# STM32WB55x register map
File version: 1.0
CPU: CM4 r0p1, little endian, 4 interrupt priority bits
Registers are 32-bit, read-write, reset 0x0 unless marked. A register's access mark holds for its fields unless they carry their own. Offsets are from the block's base; [hi:lo] are bit positions; {n}, {i} and the like mark numbered series; 'fields as' and 'values as' point back to an identical list.

## RTC
Base 0x40002800
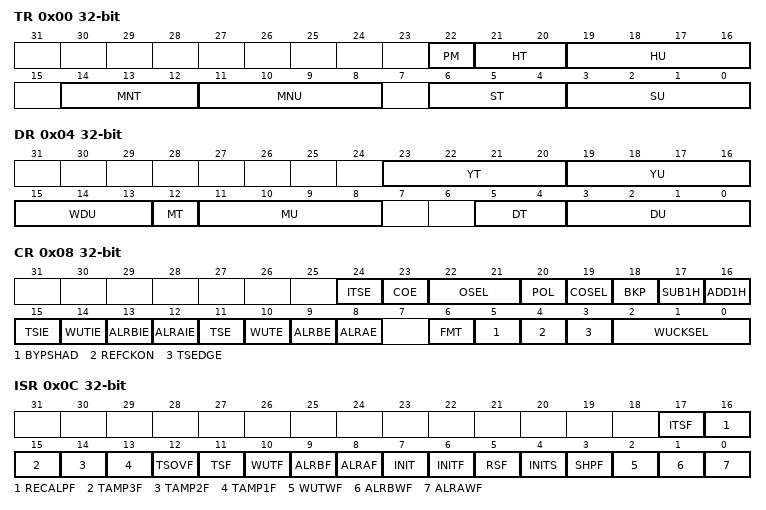
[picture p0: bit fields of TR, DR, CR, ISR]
0x00 TR
  [22] PM, [21:20] HT, [19:16] HU, [14:12] MNT, [11:8] MNU, [6:4] ST, [3:0] SU
0x04 DR
  [23:20] YT, [19:16] YU, [15:13] WDU, [12] MT, [11:8] MU, [5:4] DT, [3:0] DU
0x08 CR
  [24] ITSE, [23] COE, [22:21] OSEL, [20] POL, [19] COSEL, [18] BKP, [17] SUB1H, [16] ADD1H, [15] TSIE, [14] WUTIE, [13] ALRBIE, [12] ALRAIE, [11] TSE, [10] WUTE, [9] ALRBE, [8] ALRAE, [6] FMT, [5] BYPSHAD, [4] REFCKON, [3] TSEDGE, [2:0] WUCKSEL
0x0C ISR
  [17] ITSF, [16] RECALPF, [15] TAMP3F, [14] TAMP2F, [13] TAMP1F, [12] TSOVF, [11] TSF, [10] WUTF, [9] ALRBF, [8] ALRAF, [7] INIT, [6] INITF, [5] RSF, [4] INITS, [3] SHPF, [2] WUTWF, [1] ALRBWF, [0] ALRAWF
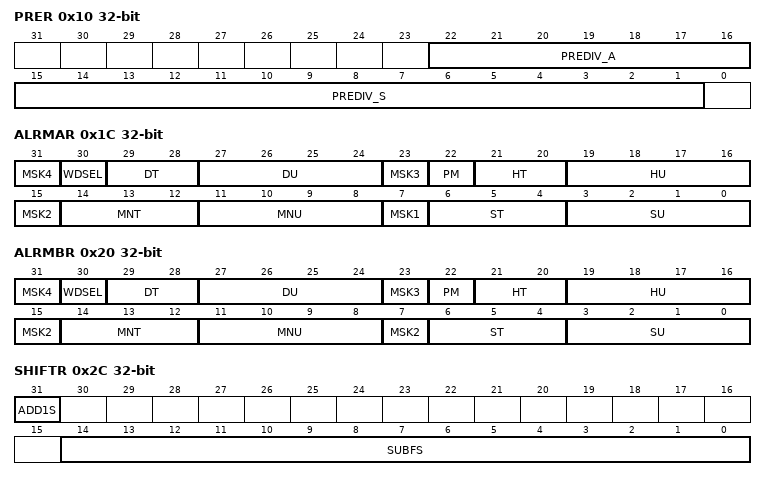
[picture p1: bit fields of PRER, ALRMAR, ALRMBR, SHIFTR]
0x10 PRER
  [22:16] PREDIV_A, [15:1] PREDIV_S
0x14 WUTR
  [15:0] WUT
0x1C ALRMAR
  [8n-1] MSK{n} (n=1..4), [30] WDSEL, [29:28] DT, [27:24] DU, [22] PM, [21:20] HT, [19:16] HU, [14:12] MNT, [11:8] MNU, [6:4] ST, [3:0] SU
0x20 ALRMBR
  [31] MSK4, [30] WDSEL, [29:28] DT, [27:24] DU, [23] MSK3, [22] PM, [21:20] HT, [19:16] HU, [15] MSK2, [14:12] MNT, [11:8] MNU, [7] MSK2, [6:4] ST, [3:0] SU
0x24 WPR
  [7:0] KEY
0x28 SSR
  [15:0] SS
0x2C SHIFTR
  [31] ADD1S, [14:0] SUBFS
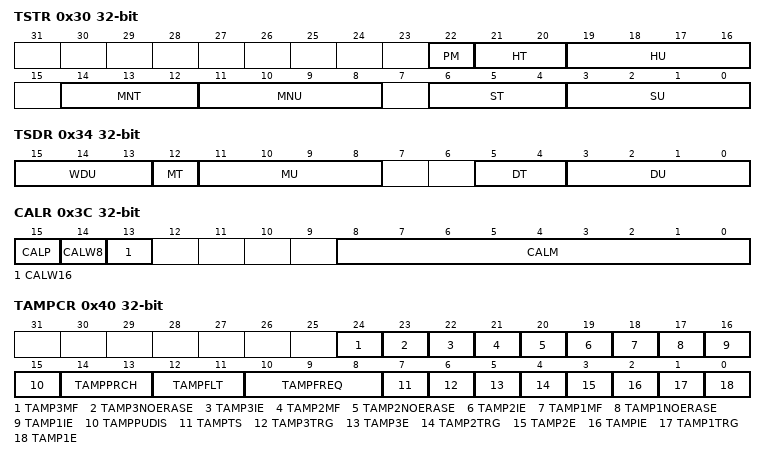
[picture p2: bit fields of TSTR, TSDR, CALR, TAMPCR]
0x30 TSTR
  fields as TR
0x34 TSDR
  [15:13] WDU, [12] MT, [11:8] MU, [5:4] DT, [3:0] DU
0x38 TSSSR
  [15:0] SS
0x3C CALR
  [15] CALP, [14] CALW8, [13] CALW16, [8:0] CALM
0x40 TAMPCR
  [24] TAMP3MF, [23] TAMP3NOERASE, [22] TAMP3IE, [21] TAMP2MF, [20] TAMP2NOERASE, [19] TAMP2IE, [18] TAMP1MF, [17] TAMP1NOERASE, [16] TAMP1IE, [15] TAMPPUDIS, [14:13] TAMPPRCH, [12:11] TAMPFLT, [10:8] TAMPFREQ, [7] TAMPTS, [6] TAMP3TRG, [5] TAMP3E, [4] TAMP2TRG, [3] TAMP2E, [2] TAMPIE, [1] TAMP1TRG, [0] TAMP1E
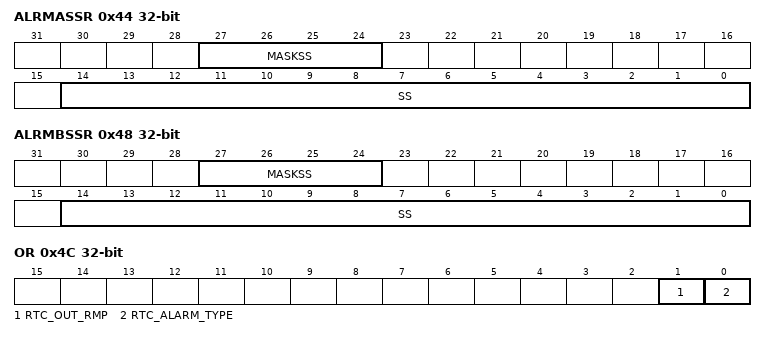
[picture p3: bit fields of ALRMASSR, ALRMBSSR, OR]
0x44 ALRMASSR
  [27:24] MASKSS, [14:0] SS
0x48 ALRMBSSR
  [27:24] MASKSS, [14:0] SS
0x4C OR
  [1] RTC_OUT_RMP, [0] RTC_ALARM_TYPE
0x50 BKP0R
  [31:0] BKP
{0x50+4i} RKP{i}R (i=1..18)
  [31:0] BKP
0x9C BKP19R
  [31:0] BKP

## GPIOA
Base 0x48000000
Same registers: GPIOB 0x48000400, GPIOC 0x48000800, GPIOD 0x48000C00, GPIOE 0x48001000, GPIOH 0x48001C00
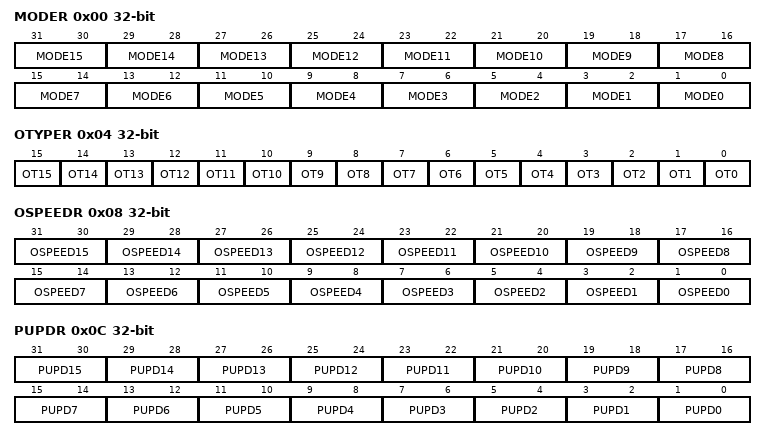
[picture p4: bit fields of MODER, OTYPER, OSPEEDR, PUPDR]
0x00 MODER
  [2n+1:2n] MODE{n} (n=0..15)
0x04 OTYPER
  [n] OT{n} (n=0..15)
0x08 OSPEEDR
  [2n+1:2n] OSPEED{n} (n=0..15)
0x0C PUPDR
  [2n+1:2n] PUPD{n} (n=0..15)
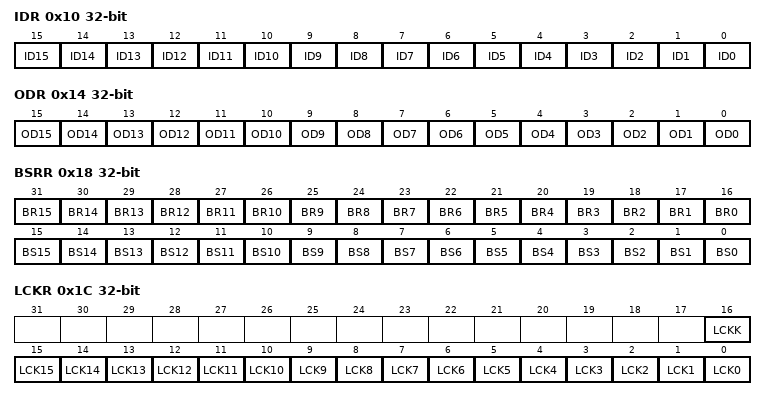
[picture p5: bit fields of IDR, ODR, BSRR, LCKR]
0x10 IDR
  [n] ID{n} (n=0..15)
0x14 ODR
  [n] OD{n} (n=0..15)
0x18 BSRR
  [n+16] BR{n} (n=0..15), [n] BS{n} (n=0..15)
0x1C LCKR
  [16] LCKK, [n] LCK{n} (n=0..15)
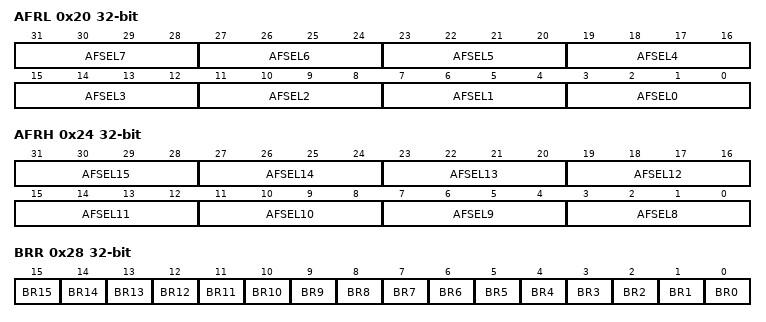
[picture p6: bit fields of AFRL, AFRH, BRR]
0x20 AFRL
  [4n+3:4n] AFSEL{n} (n=0..7)
0x24 AFRH
  [4n-29:4n-32] AFSEL{n} (n=8..15)
0x28 BRR
  [n] BR{n} (n=0..15)

## TIM1
Base 0x40012C00
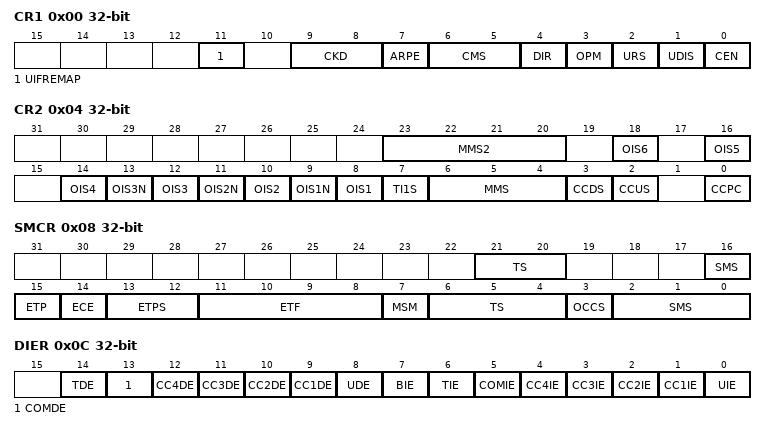
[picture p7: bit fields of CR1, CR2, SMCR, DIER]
0x00 CR1
  [11] UIFREMAP, [9:8] CKD, [7] ARPE, [6:5] CMS, [4] DIR, [3] OPM, [2] URS, [1] UDIS, [0] CEN
0x04 CR2
  [23:20] MMS2, [2n+6] OIS{n} (n=1..6), [13] OIS3N, [11] OIS2N, [9] OIS1N, [7] TI1S, [6:4] MMS, [3] CCDS, [2] CCUS, [0] CCPC
0x08 SMCR
  [21:20] TS, [16] SMS, [15] ETP, [14] ECE, [13:12] ETPS, [11:8] ETF, [7] MSM, [6:4] TS, [3] OCCS, [2:0] SMS
0x0C DIER
  [14] TDE, [13] COMDE, [n+8] CC{n}DE (n=1..4), [8] UDE, [7] BIE, [6] TIE, [5] COMIE, [n] CC{n}IE (n=1..4), [0] UIE
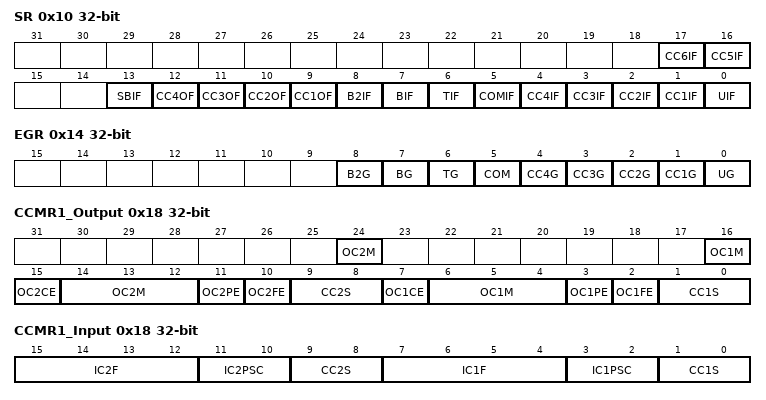
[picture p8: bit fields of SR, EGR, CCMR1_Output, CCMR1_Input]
0x10 SR
  [17] CC6IF, [16] CC5IF, [13] SBIF, [n+8] CC{n}OF (n=1..4), [8] B2IF, [7] BIF, [6] TIF, [5] COMIF, [n] CC{n}IF (n=1..4), [0] UIF
0x14 EGR
  [8] B2G, [7] BG, [6] TG, [5] COM, [n] CC{n}G (n=1..4), [0] UG
0x18 CCMR1_Output
  [24] OC2M, [16] OC1M, [15] OC2CE, [14:12] OC2M, [11] OC2PE, [10] OC2FE, [9:8] CC2S, [7] OC1CE, [6:4] OC1M, [3] OC1PE, [2] OC1FE, [1:0] CC1S
0x18 CCMR1_Input
  [15:12] IC2F, [11:10] IC2PSC, [9:8] CC2S, [7:4] IC1F, [3:2] IC1PSC, [1:0] CC1S
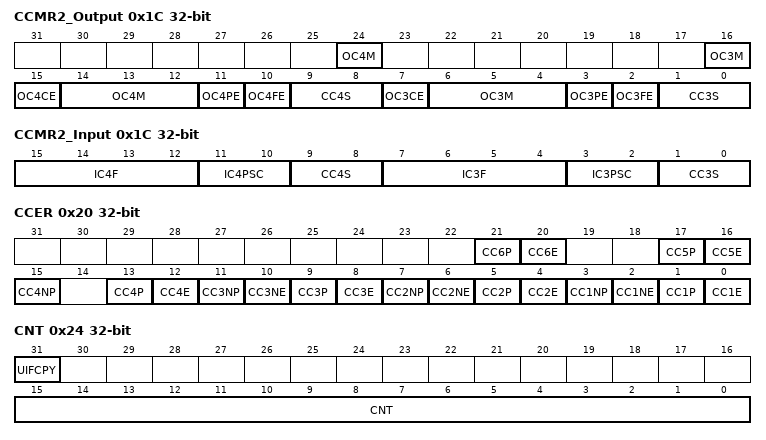
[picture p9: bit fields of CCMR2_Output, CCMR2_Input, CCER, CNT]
0x1C CCMR2_Output
  [24] OC4M, [16] OC3M, [15] OC4CE, [14:12] OC4M, [11] OC4PE, [10] OC4FE, [9:8] CC4S, [7] OC3CE, [6:4] OC3M, [3] OC3PE, [2] OC3FE, [1:0] CC3S
0x1C CCMR2_Input
  [15:12] IC4F, [11:10] IC4PSC, [9:8] CC4S, [7:4] IC3F, [3:2] IC3PSC, [1:0] CC3S
0x20 CCER
  [4n-3] CC{n}P (n=1..6), [4n-4] CC{n}E (n=1..6), [4n-1] CC{n}NP (n=1..4), [10] CC3NE, [6] CC2NE, [2] CC1NE
0x24 CNT
  [31] UIFCPY, [15:0] CNT
0x28 PSC
  [15:0] PSC
0x2C ARR
  [15:0] ARR
0x30 RCR
  [15:0] REP
{0x30+4i} CCR{i} (i=1..4)
  [15:0] CCR{i}
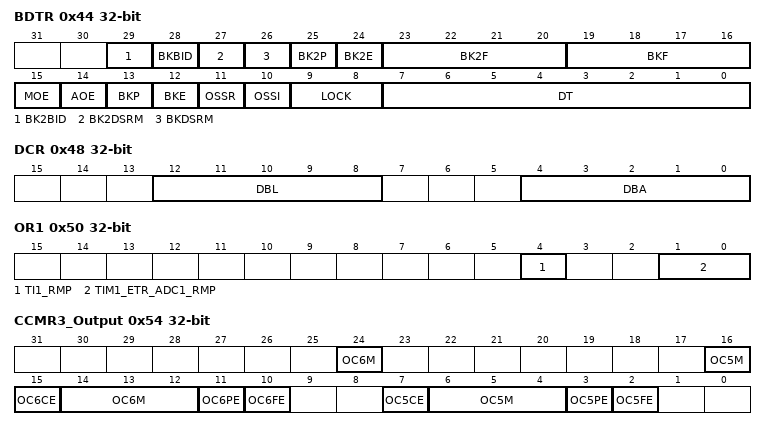
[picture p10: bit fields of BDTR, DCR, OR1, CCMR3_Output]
0x44 BDTR
  [29] BK2BID, [28] BKBID, [27] BK2DSRM, [26] BKDSRM, [25] BK2P, [24] BK2E, [23:20] BK2F, [19:16] BKF, [15] MOE, [14] AOE, [13] BKP, [12] BKE, [11] OSSR, [10] OSSI, [9:8] LOCK, [7:0] DT
0x48 DCR
  [12:8] DBL, [4:0] DBA
0x4C DMAR
  [31:0] DMAB
0x50 OR1
  [4] TI1_RMP, [1:0] TIM1_ETR_ADC1_RMP
0x54 CCMR3_Output
  [24] OC6M, [16] OC5M, [15] OC6CE, [14:12] OC6M, [11] OC6PE, [10] OC6FE, [7] OC5CE, [6:4] OC5M, [3] OC5PE, [2] OC5FE
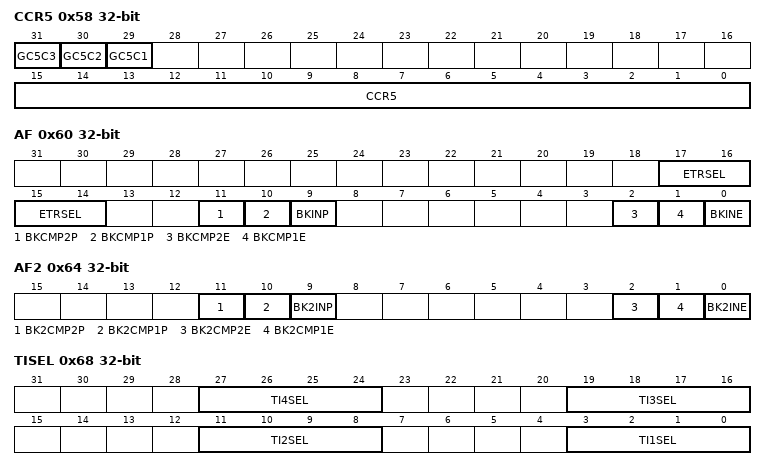
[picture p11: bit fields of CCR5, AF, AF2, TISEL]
0x58 CCR5
  [31] GC5C3, [30] GC5C2, [29] GC5C1, [15:0] CCR5
0x5C CCR6
  [15:0] CCR6
0x60 AF
  [17:14] ETRSEL, [11] BKCMP2P, [10] BKCMP1P, [9] BKINP, [2] BKCMP2E, [1] BKCMP1E, [0] BKINE
0x64 AF2
  [11] BK2CMP2P, [10] BK2CMP1P, [9] BK2INP, [2] BK2CMP2E, [1] BK2CMP1E, [0] BK2INE
0x68 TISEL
  [8n-5:8n-8] TI{n}SEL (n=1..4)
